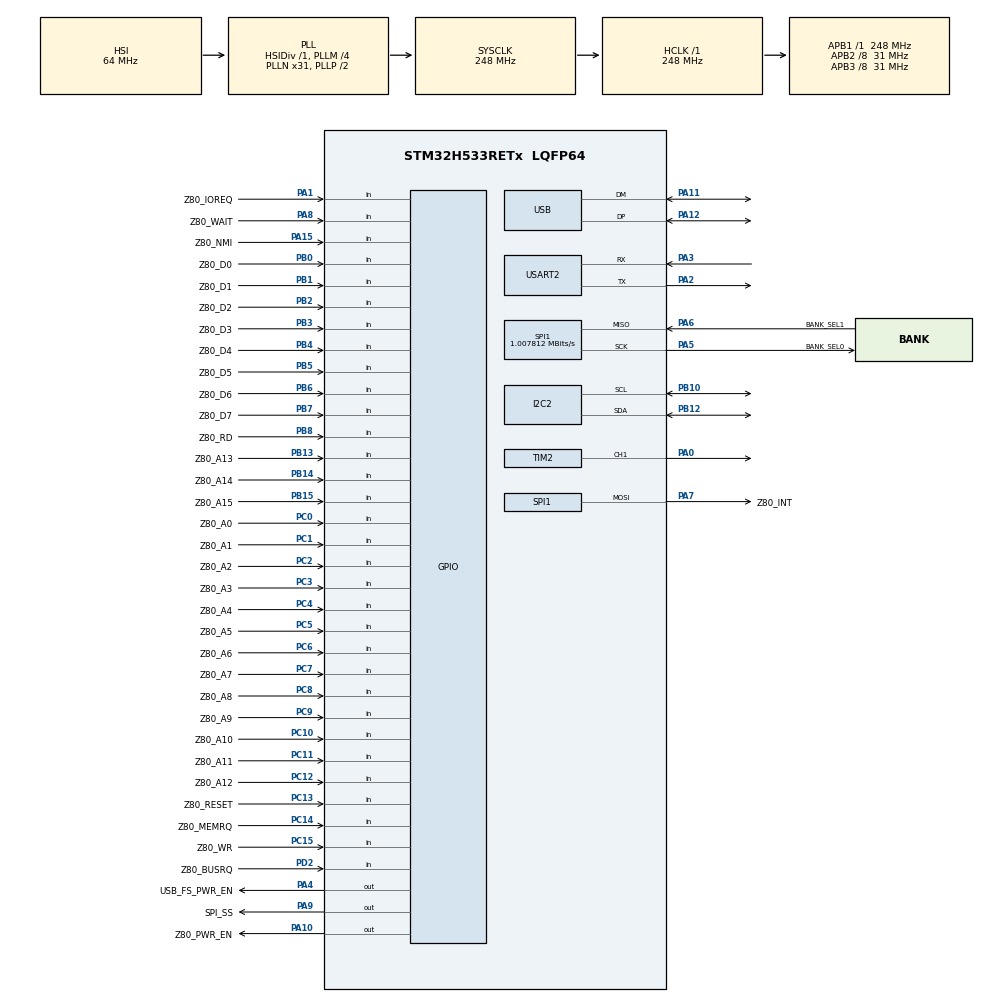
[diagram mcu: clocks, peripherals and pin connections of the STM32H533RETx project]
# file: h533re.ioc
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BOOTPATH.BootPathName=LEGACY
BOOTPATH.UserSelectedBootPath=LEGACY
CORTEX_M33_NS.userName=CORTEX_M33
I2C2.Timing=0x40C0E9FF
Mcu.Family=STM32H5
Mcu.Name=STM32H533RETx
Mcu.Package=LQFP64
NVIC.PriorityGroup=NVIC_PRIORITYGROUP_4
NVIC.TIM1_UP_IRQn=true\:15\:0\:false\:false\:true\:false\:false\:true\:true
NVIC.TimeBase=TIM1_UP_IRQn
NVIC.TimeBaseIP=TIM1
NVIC.USART2_IRQn=true\:0\:0\:false\:false\:true\:false\:true\:true\:true
NVIC.USB_DRD_FS_IRQn=true\:0\:0\:false\:false\:true\:false\:true\:true\:true
PA0.Signal=S_TIM2_CH1
PA1.GPIO_Label=Z80_IOREQ
PA1.Signal=GPIO_Input
PA10.GPIO_Label=Z80_PWR_EN
PA10.Signal=GPIO_Output
PA11.Mode=Host
PA11.Signal=USB_DM
PA12.Mode=Host
PA12.Signal=USB_DP
PA15(JTDI).GPIO_Label=Z80_NMI
PA15(JTDI).Signal=GPIO_Input
PA2.Mode=Asynchronous
PA2.Signal=USART2_TX
PA3.Mode=Asynchronous
PA3.Signal=USART2_RX
PA4.GPIO_Label=USB_FS_PWR_EN
PA4.Signal=GPIO_Output
PA5.GPIO_Label=BANK_SEL0
PA5.Mode=Full_Duplex_Master
PA5.Signal=SPI1_SCK
PA6.GPIO_Label=BANK_SEL1
PA6.Mode=Full_Duplex_Master
PA6.Signal=SPI1_MISO
PA7.GPIO_Label=Z80_INT
PA7.Mode=Full_Duplex_Master
PA7.Signal=SPI1_MOSI
PA8.GPIO_Label=Z80_WAIT
PA8.Signal=GPIO_Input
PA9.GPIO_Label=SPI_SS
PA9.PinState=GPIO_PIN_SET
PA9.Signal=GPIO_Output
PB0.GPIO_Label=Z80_D0
PB0.Signal=GPIO_Input
PB1.GPIO_Label=Z80_D1
PB1.Signal=GPIO_Input
PB10.Mode=I2C
PB10.Signal=I2C2_SCL
PB12.Mode=I2C
PB12.Signal=I2C2_SDA
PB13.GPIO_Label=Z80_A13
PB13.Signal=GPIO_Input
PB14.GPIO_Label=Z80_A14
PB14.Signal=GPIO_Input
PB15.GPIO_Label=Z80_A15
PB15.Signal=GPIO_Input
PB2.GPIO_Label=Z80_D2
PB2.Signal=GPIO_Input
PB3(JTDO/TRACESWO).GPIO_Label=Z80_D3
PB3(JTDO/TRACESWO).Signal=GPIO_Input
PB4(NJTRST).GPIO_Label=Z80_D4
PB4(NJTRST).Signal=GPIO_Input
PB5.GPIO_Label=Z80_D5
PB5.Signal=GPIO_Input
PB6.GPIO_Label=Z80_D6
PB6.Signal=GPIO_Input
PB7.GPIO_Label=Z80_D7
PB7.Signal=GPIO_Input
PB8.GPIO_Label=Z80_RD
PB8.Signal=GPIO_Input
PC0.GPIO_Label=Z80_A0
PC0.Signal=GPIO_Input
PC1.GPIO_Label=Z80_A1
PC1.Signal=GPIO_Input
PC10.GPIO_Label=Z80_A10
PC10.Signal=GPIO_Input
PC11.GPIO_Label=Z80_A11
PC11.Signal=GPIO_Input
PC12.GPIO_Label=Z80_A12
PC12.Signal=GPIO_Input
PC13.GPIO_Label=Z80_RESET
PC13.Signal=GPIO_Input
PC14-OSC32_IN(OSC32_IN).GPIO_Label=Z80_MEMRQ
PC14-OSC32_IN(OSC32_IN).Signal=GPIO_Input
PC15-OSC32_OUT(OSC32_OUT).GPIO_Label=Z80_WR
PC15-OSC32_OUT(OSC32_OUT).Signal=GPIO_Input
PC2.GPIO_Label=Z80_A2
PC2.Signal=GPIO_Input
PC3.GPIO_Label=Z80_A3
PC3.Signal=GPIO_Input
PC4.GPIO_Label=Z80_A4
PC4.Signal=GPIO_Input
PC5.GPIO_Label=Z80_A5
PC5.Signal=GPIO_Input
PC6.GPIO_Label=Z80_A6
PC6.Signal=GPIO_Input
PC7.GPIO_Label=Z80_A7
PC7.Signal=GPIO_Input
PC8.GPIO_Label=Z80_A8
PC8.Signal=GPIO_Input
PC9.GPIO_Label=Z80_A9
PC9.Signal=GPIO_Input
PD2.GPIO_Label=Z80_BUSRQ
PD2.Signal=GPIO_Input
ProjectManager.HeapSize=0x200
ProjectManager.StackSize=0x400
ProjectManager.TargetToolchain=STM32CubeIDE
RCC.ADCFreq_Value=248000000
RCC.AHBFreq_Value=248000000
RCC.APB1Freq_Value=248000000
RCC.APB1TimFreq_Value=248000000
RCC.APB2CLKDivider=RCC_HCLK_DIV8
RCC.APB2Freq_Value=31000000
RCC.APB2TimFreq_Value=62000000
RCC.APB3CLKDivider=RCC_HCLK_DIV8
RCC.APB3Freq_Value=31000000
RCC.CSI_VALUE=4000000
RCC.CortexFreq_Value=248000000
RCC.EPOD_VALUE=64000000
RCC.HCLKFreq_Value=248000000
RCC.HSE_VALUE=25000000
RCC.HSI48_VALUE=48000000
RCC.HSIDiv=RCC_HSI_DIV1
RCC.HSI_VALUE=64000000
RCC.LSE_VALUE=32768
RCC.LSIRC_VALUE=32000
RCC.PLL2P=8
RCC.PLLM=4
RCC.PLLN=31
RCC.PLLSourceVirtual=RCC_PLL1_SOURCE_HSI
RCC.SPI1CLockSelection=RCC_SPI1CLKSOURCE_PLL2P
RCC.SYSCLKFreq_VALUE=248000000
RCC.SYSCLKSource=RCC_SYSCLKSOURCE_PLLCLK
RCC.USBFreq_Value=48000000
RCC.VCOOutputFreq_Value=496000000
SH.S_TIM2_CH1.0=TIM2_CH1,PWM Generation1 CH1
SPI1.BaudRatePrescaler=SPI_BAUDRATEPRESCALER_64
SPI1.CalculateBaudRate=1.007812 MBits/s
SPI1.DataSize=SPI_DATASIZE_8BIT
SPI1.Direction=SPI_DIRECTION_2LINES
SPI1.MasterKeepIOState=SPI_MASTER_KEEP_IO_STATE_ENABLE
SPI1.Mode=SPI_MODE_MASTER
SPI1.VirtualType=VM_MASTER
THREADX.TX_TIMER_PROCESS_IN_ISR=0
TIM2.Channel-PWM\ Generation1\ CH1=TIM_CHANNEL_1
TIM2.PeriodNoDither=247
TIM2.PulseNoDither_1=124
USART2.VirtualMode-Asynchronous=VM_ASYNC
USB.VirtualMode=Host_Only
USBX.BSP.number=2
USBX.Core_System=1
USBX.USBX_HOST_SYS_SIZE=0x8000
USBX.UX_HOST_APP_MEM_POOL_SIZE=0xA000
USBX.UX_Host_Controller=1
USBX.UX_Host_CoreStack=1
USBX.UX_Host_class_HUB=1
USBX0.BSP.STBoard=false
USBX0.BSP.api=Unknown
USBX0.BSP.condition=\!USBPD_USB_SUPPORT
USBX0.BSP.instance=PA4
USBX0.BSP.ip=GPIO
USBX0.BSP.mode=Output
USBX0.BSP.name=Drive_VBUS_FS
USBX0.BSP.solution=PA4
USBX1.BSP.STBoard=false
USBX1.BSP.api=Unknown
USBX1.BSP.instance=USB
USBX1.BSP.ip=USB
USBX1.BSP.mode=Host_Only
USBX1.BSP.name=USB_Host
USBX1.BSP.solution=USB
VP_BOOTPATH_VS_BOOTPATH.Mode=BP_Activate
VP_CORTEX_M33_NS_VS_Hclk.Mode=Hclk_Mode
VP_ICACHE_VS_ICACHE.Mode=DirectMappedCache
VP_MEMORYMAP_VS_MEMORYMAP.Mode=CurAppReg
VP_PWR_VS_LPOM.Mode=PowerOptimisation
VP_PWR_VS_SECSignals.Mode=Security/Privilege
VP_SYS_VS_tim1.Mode=TIM1
VP_THREADX_VS_RTOSJjThreadXJjCoreJjDefault.Mode=Core_Default
VP_TIM2_VS_ClockSourceINT.Mode=Internal
VP_USBX_Core_System.Mode=Core_System
VP_USBX_UX\ Host\ Controller_FS.Mode=UX_Host_Controller_FS
VP_USBX_UX\ Host\ CoreStack_FS.Mode=UX_Host_CoreStack_FS
VP_USBX_UX\ Host\ HUB_FS.Mode=UX_Host_class_HUB_FS
board=custom

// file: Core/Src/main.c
/* USER CODE BEGIN Header */
/**
  ******************************************************************************
  * @file           : main.c
  * @brief          : Main program body
  ******************************************************************************
  * @attention
  *
  * Copyright (c) 2026 STMicroelectronics.
  * All rights reserved.
  *
  * This software is licensed under terms that can be found in the LICENSE file
  * in the root directory of this software component.
  * If no LICENSE file comes with this software, it is provided AS-IS.
  *
  ******************************************************************************
  */
/* USER CODE END Header */
#include "app_threadx.h"
#include "main.h"

/* USER CODE BEGIN Includes */
#include <stdio.h>
#include "nucleo64_z80/nucleo64_z80.h"

/* USER CODE END Includes */

I2C_HandleTypeDef hi2c2;

SPI_HandleTypeDef hspi1;

TIM_HandleTypeDef htim2;

UART_HandleTypeDef huart2;

HCD_HandleTypeDef hhcd_USB_DRD_FS;

void SystemClock_Config(void);
static void MX_GPIO_Init(void);
static void MX_I2C2_Init(void);
static void MX_ICACHE_Init(void);
static void MX_TIM2_Init(void);
static void MX_USART2_UART_Init(void);
static void MX_SPI1_Init(void);

int main(void)
{

  /* MCU Configuration--------------------------------------------------------*/

  /* Reset of all peripherals, Initializes the Flash interface and the Systick. */
  HAL_Init();

  /* Configure the system clock */
  SystemClock_Config();

  /* Initialize all configured peripherals */
  MX_GPIO_Init();
  MX_I2C2_Init();
  MX_ICACHE_Init();
  MX_TIM2_Init();
  MX_USART2_UART_Init();
  MX_SPI1_Init();
  /* USER CODE BEGIN 2 */
  uart_start(&huart2);
  printf("\r\nNucleo64 Z80 H533RE\r\n");
  HAL_TIM_PWM_Start(&htim2, TIM_CHANNEL_1);

  /* USER CODE END 2 */

  MX_ThreadX_Init();

  /* We should never get here as control is now taken by the scheduler */

  /* Infinite loop */
  while (1)
  {

  }
}

void SystemClock_Config(void)
{
  RCC_OscInitTypeDef RCC_OscInitStruct = {0};
  RCC_ClkInitTypeDef RCC_ClkInitStruct = {0};

  /** Configure the main internal regulator output voltage
  */
  __HAL_PWR_VOLTAGESCALING_CONFIG(PWR_REGULATOR_VOLTAGE_SCALE0);

  while(!__HAL_PWR_GET_FLAG(PWR_FLAG_VOSRDY)) {}

  /** Initializes the RCC Oscillators according to the specified parameters
  * in the RCC_OscInitTypeDef structure.
  */
  RCC_OscInitStruct.OscillatorType = RCC_OSCILLATORTYPE_HSI48|RCC_OSCILLATORTYPE_HSI
                              |RCC_OSCILLATORTYPE_CSI;
  RCC_OscInitStruct.HSIState = RCC_HSI_ON;
  RCC_OscInitStruct.HSIDiv = RCC_HSI_DIV1;
  RCC_OscInitStruct.HSICalibrationValue = RCC_HSICALIBRATION_DEFAULT;
  RCC_OscInitStruct.HSI48State = RCC_HSI48_ON;
  RCC_OscInitStruct.CSIState = RCC_CSI_ON;
  RCC_OscInitStruct.CSICalibrationValue = RCC_CSICALIBRATION_DEFAULT;
  RCC_OscInitStruct.PLL.PLLState = RCC_PLL_ON;
  RCC_OscInitStruct.PLL.PLLSource = RCC_PLL1_SOURCE_HSI;
  RCC_OscInitStruct.PLL.PLLM = 4;
  RCC_OscInitStruct.PLL.PLLN = 31;
  RCC_OscInitStruct.PLL.PLLP = 2;
  RCC_OscInitStruct.PLL.PLLQ = 2;
  RCC_OscInitStruct.PLL.PLLR = 2;
  RCC_OscInitStruct.PLL.PLLRGE = RCC_PLL1_VCIRANGE_3;
  RCC_OscInitStruct.PLL.PLLVCOSEL = RCC_PLL1_VCORANGE_WIDE;
  RCC_OscInitStruct.PLL.PLLFRACN = 0;
  if (HAL_RCC_OscConfig(&RCC_OscInitStruct) != HAL_OK)
  {
    Error_Handler();
  }

  /** Initializes the CPU, AHB and APB buses clocks
  */
  RCC_ClkInitStruct.ClockType = RCC_CLOCKTYPE_HCLK|RCC_CLOCKTYPE_SYSCLK
                              |RCC_CLOCKTYPE_PCLK1|RCC_CLOCKTYPE_PCLK2
                              |RCC_CLOCKTYPE_PCLK3;
  RCC_ClkInitStruct.SYSCLKSource = RCC_SYSCLKSOURCE_PLLCLK;
  RCC_ClkInitStruct.AHBCLKDivider = RCC_SYSCLK_DIV1;
  RCC_ClkInitStruct.APB1CLKDivider = RCC_HCLK_DIV1;
  RCC_ClkInitStruct.APB2CLKDivider = RCC_HCLK_DIV8;
  RCC_ClkInitStruct.APB3CLKDivider = RCC_HCLK_DIV8;

  if (HAL_RCC_ClockConfig(&RCC_ClkInitStruct, FLASH_LATENCY_5) != HAL_OK)
  {
    Error_Handler();
  }

  /** Configure the programming delay
  */
  __HAL_FLASH_SET_PROGRAM_DELAY(FLASH_PROGRAMMING_DELAY_2);
}

static void MX_I2C2_Init(void)
{

  hi2c2.Instance = I2C2;
  hi2c2.Init.Timing = 0x40C0E9FF;
  hi2c2.Init.OwnAddress1 = 0;
  hi2c2.Init.AddressingMode = I2C_ADDRESSINGMODE_7BIT;
  hi2c2.Init.DualAddressMode = I2C_DUALADDRESS_DISABLE;
  hi2c2.Init.OwnAddress2 = 0;
  hi2c2.Init.OwnAddress2Masks = I2C_OA2_NOMASK;
  hi2c2.Init.GeneralCallMode = I2C_GENERALCALL_DISABLE;
  hi2c2.Init.NoStretchMode = I2C_NOSTRETCH_DISABLE;
  if (HAL_I2C_Init(&hi2c2) != HAL_OK)
  {
    Error_Handler();
  }

  /** Configure Analogue filter
  */
  if (HAL_I2CEx_ConfigAnalogFilter(&hi2c2, I2C_ANALOGFILTER_ENABLE) != HAL_OK)
  {
    Error_Handler();
  }

  /** Configure Digital filter
  */
  if (HAL_I2CEx_ConfigDigitalFilter(&hi2c2, 0) != HAL_OK)
  {
    Error_Handler();
  }

}

static void MX_ICACHE_Init(void)
{

  /** Enable instruction cache in 1-way (direct mapped cache)
  */
  if (HAL_ICACHE_ConfigAssociativityMode(ICACHE_1WAY) != HAL_OK)
  {
    Error_Handler();
  }
  if (HAL_ICACHE_Enable() != HAL_OK)
  {
    Error_Handler();
  }

}

static void MX_SPI1_Init(void)
{

  /* SPI1 parameter configuration*/
  hspi1.Instance = SPI1;
  hspi1.Init.Mode = SPI_MODE_MASTER;
  hspi1.Init.Direction = SPI_DIRECTION_2LINES;
  hspi1.Init.DataSize = SPI_DATASIZE_8BIT;
  hspi1.Init.CLKPolarity = SPI_POLARITY_LOW;
  hspi1.Init.CLKPhase = SPI_PHASE_1EDGE;
  hspi1.Init.NSS = SPI_NSS_SOFT;
  hspi1.Init.BaudRatePrescaler = SPI_BAUDRATEPRESCALER_2;
  hspi1.Init.FirstBit = SPI_FIRSTBIT_MSB;
  hspi1.Init.TIMode = SPI_TIMODE_DISABLE;
  hspi1.Init.CRCCalculation = SPI_CRCCALCULATION_DISABLE;
  hspi1.Init.CRCPolynomial = 0x7;
  hspi1.Init.NSSPMode = SPI_NSS_PULSE_ENABLE;
  hspi1.Init.NSSPolarity = SPI_NSS_POLARITY_LOW;
  hspi1.Init.FifoThreshold = SPI_FIFO_THRESHOLD_01DATA;
  hspi1.Init.MasterSSIdleness = SPI_MASTER_SS_IDLENESS_00CYCLE;
  hspi1.Init.MasterInterDataIdleness = SPI_MASTER_INTERDATA_IDLENESS_00CYCLE;
  hspi1.Init.MasterReceiverAutoSusp = SPI_MASTER_RX_AUTOSUSP_DISABLE;
  hspi1.Init.MasterKeepIOState = SPI_MASTER_KEEP_IO_STATE_DISABLE;
  hspi1.Init.IOSwap = SPI_IO_SWAP_DISABLE;
  hspi1.Init.ReadyMasterManagement = SPI_RDY_MASTER_MANAGEMENT_INTERNALLY;
  hspi1.Init.ReadyPolarity = SPI_RDY_POLARITY_HIGH;
  if (HAL_SPI_Init(&hspi1) != HAL_OK)
  {
    Error_Handler();
  }

}

static void MX_TIM2_Init(void)
{

  TIM_ClockConfigTypeDef sClockSourceConfig = {0};
  TIM_MasterConfigTypeDef sMasterConfig = {0};
  TIM_OC_InitTypeDef sConfigOC = {0};

  htim2.Instance = TIM2;
  htim2.Init.Prescaler = 0;
  htim2.Init.CounterMode = TIM_COUNTERMODE_UP;
  htim2.Init.Period = 247;
  htim2.Init.ClockDivision = TIM_CLOCKDIVISION_DIV1;
  htim2.Init.AutoReloadPreload = TIM_AUTORELOAD_PRELOAD_DISABLE;
  if (HAL_TIM_Base_Init(&htim2) != HAL_OK)
  {
    Error_Handler();
  }
  sClockSourceConfig.ClockSource = TIM_CLOCKSOURCE_INTERNAL;
  if (HAL_TIM_ConfigClockSource(&htim2, &sClockSourceConfig) != HAL_OK)
  {
    Error_Handler();
  }
  if (HAL_TIM_PWM_Init(&htim2) != HAL_OK)
  {
    Error_Handler();
  }
  sMasterConfig.MasterOutputTrigger = TIM_TRGO_RESET;
  sMasterConfig.MasterSlaveMode = TIM_MASTERSLAVEMODE_DISABLE;
  if (HAL_TIMEx_MasterConfigSynchronization(&htim2, &sMasterConfig) != HAL_OK)
  {
    Error_Handler();
  }
  sConfigOC.OCMode = TIM_OCMODE_PWM1;
  sConfigOC.Pulse = 124;
  sConfigOC.OCPolarity = TIM_OCPOLARITY_HIGH;
  sConfigOC.OCFastMode = TIM_OCFAST_DISABLE;
  if (HAL_TIM_PWM_ConfigChannel(&htim2, &sConfigOC, TIM_CHANNEL_1) != HAL_OK)
  {
    Error_Handler();
  }
  HAL_TIM_MspPostInit(&htim2);

}

static void MX_USART2_UART_Init(void)
{

  huart2.Instance = USART2;
  huart2.Init.BaudRate = 115200;
  huart2.Init.WordLength = UART_WORDLENGTH_8B;
  huart2.Init.StopBits = UART_STOPBITS_1;
  huart2.Init.Parity = UART_PARITY_NONE;
  huart2.Init.Mode = UART_MODE_TX_RX;
  huart2.Init.HwFlowCtl = UART_HWCONTROL_NONE;
  huart2.Init.OverSampling = UART_OVERSAMPLING_16;
  huart2.Init.OneBitSampling = UART_ONE_BIT_SAMPLE_DISABLE;
  huart2.Init.ClockPrescaler = UART_PRESCALER_DIV1;
  huart2.AdvancedInit.AdvFeatureInit = UART_ADVFEATURE_NO_INIT;
  if (HAL_UART_Init(&huart2) != HAL_OK)
  {
    Error_Handler();
  }
  if (HAL_UARTEx_SetTxFifoThreshold(&huart2, UART_TXFIFO_THRESHOLD_1_8) != HAL_OK)
  {
    Error_Handler();
  }
  if (HAL_UARTEx_SetRxFifoThreshold(&huart2, UART_RXFIFO_THRESHOLD_1_8) != HAL_OK)
  {
    Error_Handler();
  }
  if (HAL_UARTEx_DisableFifoMode(&huart2) != HAL_OK)
  {
    Error_Handler();
  }

}

void MX_USB_HCD_Init(void)
{

  hhcd_USB_DRD_FS.Instance = USB_DRD_FS;
  hhcd_USB_DRD_FS.Init.dev_endpoints = 8;
  hhcd_USB_DRD_FS.Init.Host_channels = 8;
  hhcd_USB_DRD_FS.Init.speed = USBD_FS_SPEED;
  hhcd_USB_DRD_FS.Init.phy_itface = HCD_PHY_EMBEDDED;
  hhcd_USB_DRD_FS.Init.Sof_enable = DISABLE;
  hhcd_USB_DRD_FS.Init.low_power_enable = DISABLE;
  hhcd_USB_DRD_FS.Init.vbus_sensing_enable = DISABLE;
  hhcd_USB_DRD_FS.Init.bulk_doublebuffer_enable = DISABLE;
  hhcd_USB_DRD_FS.Init.iso_singlebuffer_enable = DISABLE;
  if (HAL_HCD_Init(&hhcd_USB_DRD_FS) != HAL_OK)
  {
    Error_Handler();
  }

}

static void MX_GPIO_Init(void)
{
  GPIO_InitTypeDef GPIO_InitStruct = {0};

  /* GPIO Ports Clock Enable */
  __HAL_RCC_GPIOC_CLK_ENABLE();
  __HAL_RCC_GPIOA_CLK_ENABLE();
  __HAL_RCC_GPIOB_CLK_ENABLE();
  __HAL_RCC_GPIOD_CLK_ENABLE();

  /*Configure GPIO pin Output Level */
  HAL_GPIO_WritePin(GPIOA, USB_FS_PWR_EN_Pin|Z80_PWR_EN_Pin, GPIO_PIN_RESET);

  /*Configure GPIO pin Output Level */
  HAL_GPIO_WritePin(SPI_SS_GPIO_Port, SPI_SS_Pin, GPIO_PIN_SET);

  /*Configure GPIO pins : Z80_RESET_Pin Z80_MEMRQ_Pin Z80_WR_Pin Z80_A0_Pin
                           Z80_A1_Pin Z80_A2_Pin Z80_A3_Pin Z80_A4_Pin
                           Z80_A5_Pin Z80_A6_Pin Z80_A7_Pin Z80_A8_Pin
                           Z80_A9_Pin Z80_A10_Pin Z80_A11_Pin Z80_A12_Pin */
  GPIO_InitStruct.Pin = Z80_RESET_Pin|Z80_MEMRQ_Pin|Z80_WR_Pin|Z80_A0_Pin
                          |Z80_A1_Pin|Z80_A2_Pin|Z80_A3_Pin|Z80_A4_Pin
                          |Z80_A5_Pin|Z80_A6_Pin|Z80_A7_Pin|Z80_A8_Pin
                          |Z80_A9_Pin|Z80_A10_Pin|Z80_A11_Pin|Z80_A12_Pin;
  GPIO_InitStruct.Mode = GPIO_MODE_INPUT;
  GPIO_InitStruct.Pull = GPIO_NOPULL;
  HAL_GPIO_Init(GPIOC, &GPIO_InitStruct);

  /*Configure GPIO pins : Z80_IOREQ_Pin Z80_WAIT_Pin Z80_NMI_Pin */
  GPIO_InitStruct.Pin = Z80_IOREQ_Pin|Z80_WAIT_Pin|Z80_NMI_Pin;
  GPIO_InitStruct.Mode = GPIO_MODE_INPUT;
  GPIO_InitStruct.Pull = GPIO_NOPULL;
  HAL_GPIO_Init(GPIOA, &GPIO_InitStruct);

  /*Configure GPIO pins : USB_FS_PWR_EN_Pin SPI_SS_Pin Z80_PWR_EN_Pin */
  GPIO_InitStruct.Pin = USB_FS_PWR_EN_Pin|SPI_SS_Pin|Z80_PWR_EN_Pin;
  GPIO_InitStruct.Mode = GPIO_MODE_OUTPUT_PP;
  GPIO_InitStruct.Pull = GPIO_NOPULL;
  GPIO_InitStruct.Speed = GPIO_SPEED_FREQ_LOW;
  HAL_GPIO_Init(GPIOA, &GPIO_InitStruct);

  /*Configure GPIO pins : Z80_D0_Pin Z80_D1_Pin Z80_D2_Pin Z80_A13_Pin
                           Z80_A14_Pin Z80_A15_Pin Z80_D3_Pin Z80_D4_Pin
                           Z80_D5_Pin Z80_D6_Pin Z80_D7_Pin Z80_RD_Pin */
  GPIO_InitStruct.Pin = Z80_D0_Pin|Z80_D1_Pin|Z80_D2_Pin|Z80_A13_Pin
                          |Z80_A14_Pin|Z80_A15_Pin|Z80_D3_Pin|Z80_D4_Pin
                          |Z80_D5_Pin|Z80_D6_Pin|Z80_D7_Pin|Z80_RD_Pin;
  GPIO_InitStruct.Mode = GPIO_MODE_INPUT;
  GPIO_InitStruct.Pull = GPIO_NOPULL;
  HAL_GPIO_Init(GPIOB, &GPIO_InitStruct);

  /*Configure GPIO pin : Z80_BUSRQ_Pin */
  GPIO_InitStruct.Pin = Z80_BUSRQ_Pin;
  GPIO_InitStruct.Mode = GPIO_MODE_INPUT;
  GPIO_InitStruct.Pull = GPIO_NOPULL;
  HAL_GPIO_Init(Z80_BUSRQ_GPIO_Port, &GPIO_InitStruct);

}

/* USER CODE BEGIN 4 */
void HAL_UART_RxCpltCallback(UART_HandleTypeDef *huart)
{
    uart_rx_callback(huart);
}

/* USER CODE END 4 */

void HAL_TIM_PeriodElapsedCallback(TIM_HandleTypeDef *htim)
{
  if (htim->Instance == TIM1)
  {
    HAL_IncTick();
  }
}

void Error_Handler(void)
{
  __disable_irq();
  while (1)
  {
  }
}
